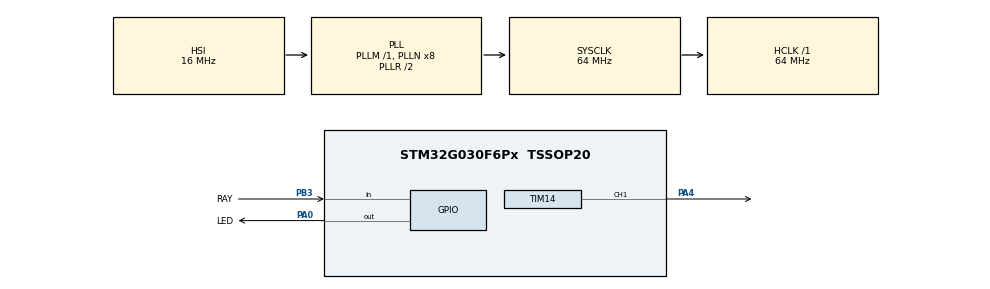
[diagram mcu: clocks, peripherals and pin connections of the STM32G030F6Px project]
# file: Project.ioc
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Mcu.Family=STM32G0
Mcu.Name=STM32G030F6Px
Mcu.Package=TSSOP20
NVIC.WWDG_IRQn=true\:0\:0\:false\:false\:true\:true\:true\:true
PA0.GPIO_Label=LED
PA0.PinState=GPIO_PIN_SET
PA0.Signal=GPIO_Output
PA13.Mode=Serial_Wire
PA13.Signal=SYS_SWDIO
PA14-BOOT0.Mode=Serial_Wire
PA14-BOOT0.Signal=SYS_SWCLK
PA14-BOOT0__PA15.StandardMode=true
PA4.Signal=S_TIM14_CH1
PB0__PB1__PB2__PA8.StandardMode=true
PB3.GPIO_Label=RAY
PB3.GPIO_PuPd=GPIO_PULLDOWN
PB3.Signal=GPIO_Input
PB3__PB4__PB5__PB6.StandardMode=true
PB7__PB8.StandardMode=true
PC14-OSC32_IN\ (PC14)__PB9.StandardMode=true
ProjectManager.HeapSize=0x200
ProjectManager.StackSize=0x400
ProjectManager.TargetToolchain=MDK-ARM V5.32
RCC.ADCFreq_Value=64000000
RCC.AHBFreq_Value=64000000
RCC.CortexFreq_Value=64000000
RCC.EXTERNAL_CLOCK_VALUE=12288000
RCC.HCLKFreq_Value=64000000
RCC.HSE_VALUE=8000000
RCC.HSI_VALUE=16000000
RCC.LSE_VALUE=32768
RCC.SYSCLKFreq_VALUE=64000000
RCC.SYSCLKSource=RCC_SYSCLKSOURCE_PLLCLK
RCC.VCOOutputFreq_Value=128000000
SH.S_TIM14_CH1.0=TIM14_CH1,PWM Generation1 CH1
TIM14.Channel=TIM_CHANNEL_1
TIM14.Period=400-1
TIM14.Prescaler=32-1
VP_TIM14_VS_ClockSourceINT.Mode=Enable_Timer
VP_WWDG_VS_WWDG.Mode=WWDG_Activate
WWDG.Counter=127
WWDG.EWIMode=WWDG_EWI_ENABLE
WWDG.Prescaler=WWDG_PRESCALER_128
board=custom

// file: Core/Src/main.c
/* USER CODE BEGIN Header */
/**
  ******************************************************************************
  * @file           : main.c
  * @brief          : Main program body
  ******************************************************************************
  * @attention
  *
  * Copyright (c) 2024 STMicroelectronics.
  * All rights reserved.
  *
  * This software is licensed under terms that can be found in the LICENSE file
  * in the root directory of this software component.
  * If no LICENSE file comes with this software, it is provided AS-IS.
  *
  ******************************************************************************
  */
/* USER CODE END Header */
#include "main.h"
#include "tim.h"
#include "wwdg.h"
#include "gpio.h"

void SystemClock_Config(void);
/* USER CODE BEGIN PFP */
void SetBreathingLight(uint32_t from, uint32_t to, uint32_t step, Direction_t direction);

/* USER CODE END PFP */

int main(void)
{

  /* MCU Configuration--------------------------------------------------------*/

  /* Reset of all peripherals, Initializes the Flash interface and the Systick. */
  HAL_Init();

  /* Configure the system clock */
  SystemClock_Config();

  /* Initialize all configured peripherals */
  MX_GPIO_Init();
  MX_WWDG_Init();
  MX_TIM14_Init();
  /* USER CODE BEGIN 2 */
  HAL_TIM_PWM_Start(&htim14, TIM_CHANNEL_1);
  HAL_GPIO_WritePin(LED_GPIO_Port, LED_Pin, GPIO_PIN_RESET);

  SetBreathingLight(0, 20, 1, DIRECTION_UP);
  HAL_Delay(1000 * 60 * 10);
  SetBreathingLight(20, 40, 1, DIRECTION_UP);
  HAL_Delay(1000 * 60 * 10);
  SetBreathingLight(40, 60, 1, DIRECTION_UP);
  HAL_Delay(1000 * 60 * 10);
  SetBreathingLight(60, 399, 1, DIRECTION_UP);
  HAL_Delay(1000 * 60 * 60);
  SetBreathingLight(399, 30, 1, DIRECTION_DOWN);

  /* USER CODE END 2 */

  /* Infinite loop */
  /* USER CODE BEGIN WHILE */
  while (1)
  {
    HAL_GPIO_TogglePin(LED_GPIO_Port, LED_Pin);
    HAL_Delay(300);

    if (HAL_GPIO_ReadPin(RAY_GPIO_Port, RAY_Pin) == GPIO_PIN_SET)
    {
      HAL_GPIO_WritePin(LED_GPIO_Port, LED_Pin, GPIO_PIN_RESET);
      SetBreathingLight(30, 399, 1, DIRECTION_UP);
      HAL_Delay(1000 * 60 * 5);
      SetBreathingLight(399, 30, 1, DIRECTION_DOWN);
    }

    /* USER CODE END WHILE */

  }
}

void SystemClock_Config(void)
{
  RCC_OscInitTypeDef RCC_OscInitStruct = {0};
  RCC_ClkInitTypeDef RCC_ClkInitStruct = {0};

  /** Configure the main internal regulator output voltage
  */
  HAL_PWREx_ControlVoltageScaling(PWR_REGULATOR_VOLTAGE_SCALE1);

  /** Initializes the RCC Oscillators according to the specified parameters
  * in the RCC_OscInitTypeDef structure.
  */
  RCC_OscInitStruct.OscillatorType = RCC_OSCILLATORTYPE_HSI;
  RCC_OscInitStruct.HSIState = RCC_HSI_ON;
  RCC_OscInitStruct.HSIDiv = RCC_HSI_DIV1;
  RCC_OscInitStruct.HSICalibrationValue = RCC_HSICALIBRATION_DEFAULT;
  RCC_OscInitStruct.PLL.PLLState = RCC_PLL_ON;
  RCC_OscInitStruct.PLL.PLLSource = RCC_PLLSOURCE_HSI;
  RCC_OscInitStruct.PLL.PLLM = RCC_PLLM_DIV1;
  RCC_OscInitStruct.PLL.PLLN = 8;
  RCC_OscInitStruct.PLL.PLLP = RCC_PLLP_DIV2;
  RCC_OscInitStruct.PLL.PLLR = RCC_PLLR_DIV2;
  if (HAL_RCC_OscConfig(&RCC_OscInitStruct) != HAL_OK)
  {
    Error_Handler();
  }

  /** Initializes the CPU, AHB and APB buses clocks
  */
  RCC_ClkInitStruct.ClockType = RCC_CLOCKTYPE_HCLK|RCC_CLOCKTYPE_SYSCLK
                              |RCC_CLOCKTYPE_PCLK1;
  RCC_ClkInitStruct.SYSCLKSource = RCC_SYSCLKSOURCE_PLLCLK;
  RCC_ClkInitStruct.AHBCLKDivider = RCC_SYSCLK_DIV1;
  RCC_ClkInitStruct.APB1CLKDivider = RCC_HCLK_DIV1;

  if (HAL_RCC_ClockConfig(&RCC_ClkInitStruct, FLASH_LATENCY_2) != HAL_OK)
  {
    Error_Handler();
  }
}

/* USER CODE BEGIN 4 */
void SetBreathingLight(uint32_t from, uint32_t to, uint32_t step, Direction_t direction)
{
  int32_t brightness = from;

  switch (direction)
  {
    case DIRECTION_UP:
      for (; brightness <= to; brightness += step)
      {
        __HAL_TIM_SET_COMPARE(&htim14, TIM_CHANNEL_1, brightness);
        HAL_Delay(10);
      }
      break;

    case DIRECTION_DOWN:
      for (; brightness >= to; brightness -= step)
      {
        __HAL_TIM_SET_COMPARE(&htim14, TIM_CHANNEL_1, brightness);
        HAL_Delay(10);
      }
      break;
  }
}

/* USER CODE END 4 */

void Error_Handler(void)
{
  __disable_irq();
  while (1)
  {
  }
}
